# DSS_L4_PER register map
Vendor: Texas Instruments
Peripheral module from a debugger description file (folder omap4430).
Registers are 32-bit, read-only, no defined reset value unless marked. A register's access mark holds for its fields unless they carry their own. Offsets are as the file gives them; lines under a group give offsets from that group; [hi:lo] are bit positions; {n}, {i} and the like mark numbered series; 'fields as' and 'values as' point back to an identical list; <NAME> marks a mode.

## DSS_L4_PER
0x00 DSS_REVISION — This register contains the DSS revision number.
  [31:0] REVISION — IP revision
0x14 DSS_SYSSTATUS reset 0x1 — This register provides status information about the module.
  [0] RESETDONE — Internal reset monitoring
    0=RESETDONE_0_r (Internal module reset is ongoing.); 1=RESETDONE_1_r (Reset complete)
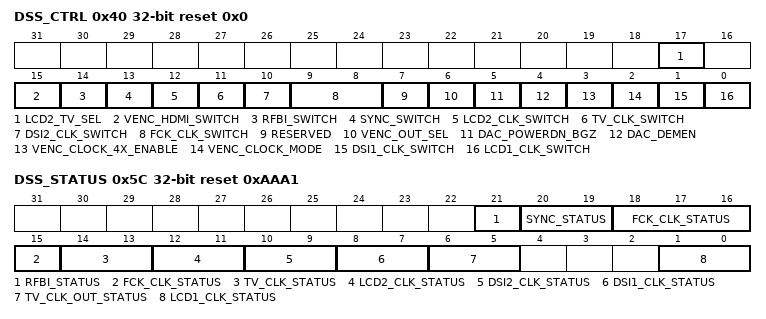
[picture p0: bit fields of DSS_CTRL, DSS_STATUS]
0x40 DSS_CTRL access per field reset 0x0 — This register contains the DSS control bits.
  [17] LCD2_TV_SEL rw — Selection between LCD2 and TV channel out on the LCD2 parallel output (multiplexer 13) 0x0: Select LCD2 channel output (default selection) 0x1: Select TV channel output
  [15] VENC_HDMI_SWITCH rw — Selects HDMI sync and associated clock or VENC and its associated TV_CLK
    0=VENC selected; 1=HDMI selected
  [14] RFBI_SWITCH rw — Selects the video port from DISPC between video port 1 and video port 2 (multiplexer 11).
    0=RFBI_SWITCH_0_r (Video port 1 (also named primary LCD output or LCD1) is selected (backward-compatible mode).); 1=RFBI_SWITCH_1_r (Video port 2 (also named secondary LCD output or LCD2) is selected.)
  [13] SYNC_SWITCH rw — Selects the sync generator for SD video (DSS VENC IP, or component VENC IP connected at the top)
    0=SYNC_SWITCH_0_r (Internal VENC IP selected); 1=SYNC_SWITCH_1_r (Component VENC IP selected)
  [12] LCD2_CLK_SWITCH rw — DSS_CLK/PLL2_CLK1 clock switch (multiplexer 3) Selects the clock source for the DISPC LCD2_CLK clock
    0=DSS_CLK selected (from PRCM); 1=PLL2_CLK1 selected
  [11] TV_CLK_SWITCH rw — DSS_TV_CLK/PLL3_CLK clock switch Selects the clock source for the VENC/HDMI functional clock
    0=PLL3_CLK1 selected (from HDMI PLL); 1=DSS_TV_CLK selected (from PAD)
  [10] DSI2_CLK_SWITCH rw — DSS_CLK/PLL2_CLK2 clock switch Selects the clock source for the DSI2 functional clock DSI2_CLK
    0=DSS_CLK selected (from PRCM); 1=PLL2_CLK2 selected (from DSI2 PLL)
  [9:8] FCK_CLK_SWITCH rw — Selects the clock source for the DISPC functional clock DISPC_FCLK
    0=DSS_CLK selected (from PRCM); 1=PLL1_CLK1 selected (from DSI1 PLL); 2=PLL2_CLK1 selected (from DSI2 PLL); 3=PLL3_CLK1 selected (from HDMI PLL)
  [7] RESERVED ro — Write 0's for future compatibility. Reads returns 0.
  [6] VENC_OUT_SEL rw — VENC mode selection for VENC output multiplexer
    0=Composite VENC output selected; 1=Luminance VENC output selected
  [5] DAC_POWERDN_BGZ rw — DAC Power-down band gap control
    0=DAC power-down band gap disabled; 1=DAC power-down band gap enabled
  [4] DAC_DEMEN rw — DAC Dynamic Element Matching Enable
    0=DAC dynamic element matching disabled; 1=DAC dynamic element matching enabled
  [3] VENC_CLOCK_4X_ENABLE rw — VENC clock CLK4X enable This bit is used to control the CLK4X clock gating.
    0=Disable; 1=Enable
  [2] VENC_CLOCK_MODE rw — VENC clock mode. See, .
    0=Clock Mode 0; 1=Clock Mode 1. In both clock modes, all three balanced clocks, derived from the TV_CLK clock, are provided to the VENC, if the VENC_CLOCK_4X_ENABLE [3] bit is set to 1 by software.
  [1] DSI1_CLK_SWITCH rw — DSS_CLK/PLL1_CLK2 clock switch Selects the clock source for the DSI1 functional clock DSI1_CLK
    0=DSS_CLK selected (from PRCM); 1=PLL1_CLK2 selected (from DSI1 PLL)
  [0] LCD1_CLK_SWITCH rw — DSS_CLK/PLL1_CLK1 clock switch (multiplexer 2) Selects the clock source for the DISPC LCD1_CLK clock
    0=DSS_CLK selected (from PRCM); 1=PLL1_CLK1 selected (from DSI1 PLL)
0x5C DSS_STATUS reset 0xAAA1 — This register contains the DSS status.
  [21] RFBI_STATUS — Video port selection status (multiplexer 11) Indicates if video port 1 or video 2 from DISPC is used to provide data to the RFBI
    0=RFBI_STATUS_0_r (Video port 1 (named also primary LCD output or LCD1) used to provide data to RFBI); 1=RFBI_STATUS_1_r (Video port 2 (named also secondary LCD output or LCD2) used to provide data to RFBI)
  [20:19] SYNC_STATUS — Sync generator selection status (multiplexer 9) Indicates if DSS VENC IP or external component VENC IP is selected as syncs generator (master mode)
    0=SYNC_STATUS_0_r (Internal VENC IP selected); 1=SYNC_STATUS_1_r (Component VENC IP selected); 2=SYNC_STATUS_2_r (HDMI IP selected)
  [18:15] FCK_CLK_STATUS — DISPC_FCLK clock selection status (multiplexer 1), indicates which clock is used by the glitch-free multiplexer selecting the source of DISPC_FCLK. The current and the new-selected clocks must be running to be able to switch. Both clocks are used at the same time while the switching is ongoing.
    0=FCK_CLK_STATUS_0_r (DSS_CLK clock switching is ongoing.); 1=FCK_CLK_STATUS_1_r (DSS_CLK is used by DISPC as DISPC_FCLK clock.); 2=FCK_CLK_STATUS_2_r (PLL1_CLK1 is used by DISPC as DISPC_FCLK clock.); 4=FCK_CLK_STATUS_4_r (PLL2_CLK1 is used by DISPC as DISPC_FCLK clock.); 8=FCK_CLK_STATUS_8_r (PLL3_CLK1 (TV_CLK) is used by DISPC as DISPC_FCLK clock.)
  [14:13] TV_CLK_STATUS — TV_CLK clock selection status (multiplexer 7), indicates which clock is used by the multiplexer selecting the source of TV_CLK. The current and the new-selected clocks must be running to be able to switch. Both clocks are used at the same time while the switching is ongoing.
    1=TV_CLK_STATUS_1_r (PLL3_CLK1 is used as TV_CLK.); 2=TV_CLK_STATUS_2_r (DSS_TV_CLK is used as TV_CLK.)
  [12:11] LCD2_CLK_STATUS — LCD2_CLK clock selection status (multiplexer 3), indicates which clock is used by the glitch-free multiplexer selecting the source of LCD2_CLK. The current and the new-selected clocks must be running to be able to switch. Both clocks are used at the same time while the switching is ongoing.
    0=LCD2_CLK_STATUS_0_r (LCD2_CLK clock switching is ongoing.); 1=LCD2_CLK_STATUS_1_r (DSS_CLK is used as LCD2_CLK.); 2=LCD2_CLK_STATUS_2_r (PLL2_CLK1 is used by DISPC as LCD2_CLK clock.)
  [10:9] DSI2_CLK_STATUS — DSI2_CLK clock selection status (multiplexer 5), indicates which clock is used by the glitch-free multiplexer selecting the source of DSI2_CLK. The current and the new-selected clocks must be running to be able to switch. Both clocks are used at the same time while the switching is ongoing.
    0=DSI2_CLK_STATUS_0_r (DSI2_CLK clock switching is ongoing); 1=DSI2_CLK_STATUS_1_r (DSS_CLK is used by DSI2 as DSI2_CLK clock.); 2=DSI2_CLK_STATUS_2_r (PLL2_CLK2 is used by DSI2 as DSI2_CLK clock.)
  [8:7] DSI1_CLK_STATUS — DSI1_CLK clock selection status (multiplexer 4), indicates which clock is used by the glitch-free multiplexer selecting the source of DSI1_CLK. The current and the new-selected clocks must be running to be able to switch. Both clocks are used at the same time while the switching is ongoing.
    0=DSI1_CLK_STATUS_0_r (DSI1_CLK clock switching is ongoing.); 1=DSI1_CLK_STATUS_1_r (DSS_CLK is used by DSI1 as DSI1_CLK clock.); 2=DSI1_CLK_STATUS_2_r (PLL1_CLK2 is used by DSI1 as DSI1_CLK clock.)
  [6:5] TV_CLK_OUT_STATUS — TV_CLK_OUT selection status (multiplexer 12) indicates which clock is used by the multiplexer selecting the TV_CLK_OUT of the DISPC. The current and the new-selected clocks must be running to be able to switch. Both clocks are used at the same time while the switching is ongoing.
    1=TV_CLK_OUT_STATUS_1_r (TV_CLK is used by DISPC as TV_CLK_OUT clock.); 2=TV_CLK_OUT_STATUS_2_r (HDMI_M_PCLK is used by DISPC as TV_CLK_OUT clock.)
  [1:0] LCD1_CLK_STATUS — LCD1_CLK clock selection status (multiplexer 2), indicates which clock is used by the glitch-free multiplexer selecting the source of LCD1_CLK. The current and the new-selected clocks must be running to be able to switch. Both clocks are used at the same time while the switching is ongoing.
    0=LCD1_CLK_STATUS_0_r (LCD1_CLK clock switching is ongoing.); 1=LCD1_CLK_STATUS_1_r (DSS_CLK is used as LCD1_CLK.); 2=LCD1_CLK_STATUS_2_r (PLL1_CLK1 is used by DISPC as LCD1_CLK clock.)
